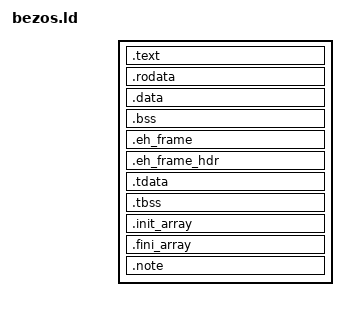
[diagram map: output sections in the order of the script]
SECTIONS
{
    .text : {
        *(.text .text.*)
    } :text

    . = ALIGN(CONSTANT(MAXPAGESIZE));

    .rodata : {
        *(.rodata .rodata.*)
    } :rodata

    . = ALIGN(CONSTANT(MAXPAGESIZE));

    .data : {
        *(.data .data.*)
    } :data

    . = ALIGN(CONSTANT(MAXPAGESIZE));

    .bss : {
        *(.bss .bss.*)
        *(COMMON)
    } :data

    . = ALIGN(CONSTANT(MAXPAGESIZE));

    .eh_frame : {
        PROVIDE_HIDDEN(__eh_frame_start = .);
        KEEP(*(.eh_frame .eh_frame.*))
        PROVIDE_HIDDEN(__eh_frame_end = .);
    }

    .eh_frame_hdr : {
        PROVIDE_HIDDEN(__eh_frame_hdr_start = .);
        KEEP(*(.eh_frame_hdr .eh_frame_hdr.*))
        PROVIDE_HIDDEN(__eh_frame_hdr_end = .);
    }

    .tdata : {
        *(.tdata .tdata.*)
    }

    .tbss : {
        *(.tbss .tbss.*)
        *(.tcommon)
    }

    .init_array : {
        PROVIDE_HIDDEN (__init_array_start = .);
        KEEP (*(SORT_BY_INIT_PRIORITY(.init_array.*) SORT_BY_INIT_PRIORITY(.ctors.*)))
        KEEP (*(.init_array EXCLUDE_FILE (*crtbegin.o *crtbegin?.o *crtend.o *crtend?.o ) .ctors))
        PROVIDE_HIDDEN (__init_array_end = .);
    }

    .fini_array : {
        PROVIDE_HIDDEN (__fini_array_start = .);
        KEEP (*(SORT_BY_INIT_PRIORITY(.fini_array.*) SORT_BY_INIT_PRIORITY(.dtors.*)))
        KEEP (*(.fini_array EXCLUDE_FILE (*crtbegin.o *crtbegin?.o *crtend.o *crtend?.o ) .dtors))
        PROVIDE_HIDDEN (__fini_array_end = .);
    }

    .note : {
        *(.note .note.*)
    }
}
